# ATSAME51J18A register map
Vendor: Microchip Technology; Series: SAME51; File version: 0
CPU: CM4 r0p1, selectable endian, MPU, FPU, 3 interrupt priority bits
Registers are 32-bit, read-write, reset 0x0 unless marked. A register's access mark holds for its fields unless they carry their own. Offsets are from the block's base; [hi:lo] are bit positions; 'fields as' and 'values as' point back to an identical list.

## RAMECC
Base 0x41020000; register names take the prefix RAMECC_
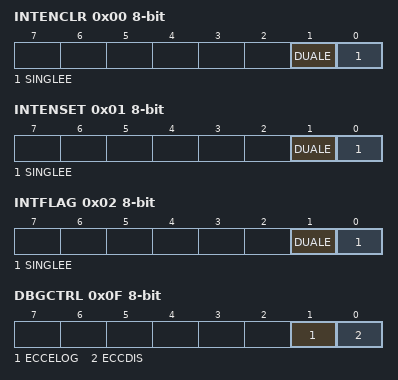
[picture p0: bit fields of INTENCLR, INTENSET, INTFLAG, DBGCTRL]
0x00 INTENCLR 8-bit — Interrupt Enable Clear
  [1] DUALE — Dual Bit ECC Error Interrupt Enable Clear
  [0] SINGLEE — Single Bit ECC Error Interrupt Enable Clear
0x01 INTENSET 8-bit — Interrupt Enable Set
  [1] DUALE — Dual Bit ECC Error Interrupt Enable Set
  [0] SINGLEE — Single Bit ECC Error Interrupt Enable Set
0x02 INTFLAG 8-bit — Interrupt Flag
  [1] DUALE — Dual Bit ECC Error Interrupt
  [0] SINGLEE — Single Bit ECC Error Interrupt
0x03 STATUS 8-bit ro
  [0] ECCDIS — ECC Disable
0x04 ERRADDR ro — Error Address
  [16:0] ERRADDR
0x0F DBGCTRL 8-bit — Debug Control
  [1] ECCELOG — ECC Error Log
  [0] ECCDIS — ECC Disable

## RSTC — Reset Controller
Base 0x40000C00; register names take the prefix RSTC_
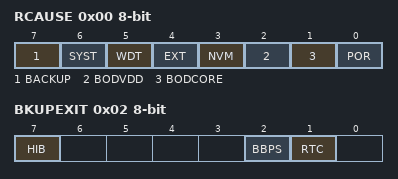
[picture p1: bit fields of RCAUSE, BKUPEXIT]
0x00 RCAUSE 8-bit ro — Reset Cause
  [7] BACKUP — Backup Reset
  [6] SYST — System Reset Request
  [5] WDT — Watchdog Reset
  [4] EXT — External Reset
  [3] NVM — NVM Reset
  [2] BODVDD — Brown Out VDD Detector Reset
  [1] BODCORE — Brown Out CORE Detector Reset
  [0] POR — Power On Reset
0x02 BKUPEXIT 8-bit ro — Backup Exit Source
  [7] HIB — Hibernate
  [2] BBPS — Battery Backup Power Switch
  [1] RTC — Real Timer Counter Interrupt

## SUPC — Supply Controller
Base 0x40001800; register names take the prefix SUPC_
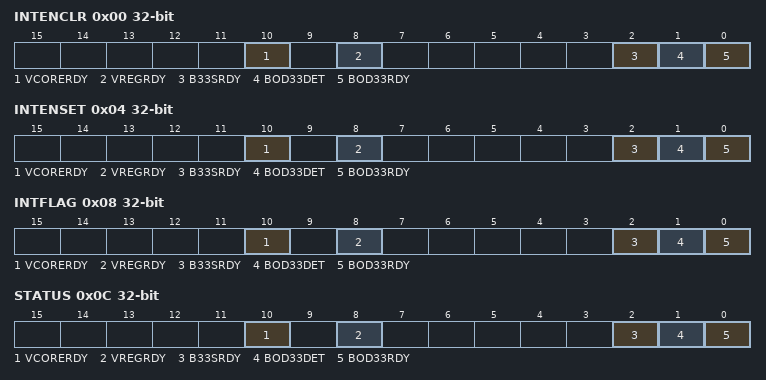
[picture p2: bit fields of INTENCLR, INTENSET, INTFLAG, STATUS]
0x00 INTENCLR — Interrupt Enable Clear
  [10] VCORERDY — VDDCORE Ready
  [8] VREGRDY — Voltage Regulator Ready
  [2] B33SRDY — BOD33 Synchronization Ready
  [1] BOD33DET — BOD33 Detection
  [0] BOD33RDY — BOD33 Ready
0x04 INTENSET — Interrupt Enable Set
  fields as INTENCLR
0x08 INTFLAG — Interrupt Flag Status and Clear
  [10] VCORERDY write-1-clears — VDDCORE Ready
  [8] VREGRDY write-1-clears — Voltage Regulator Ready
  [2] B33SRDY write-1-clears — BOD33 Synchronization Ready
  [1] BOD33DET write-1-clears — BOD33 Detection
  [0] BOD33RDY write-1-clears — BOD33 Ready
0x0C STATUS ro — Power and Clocks Status
  fields as INTENCLR
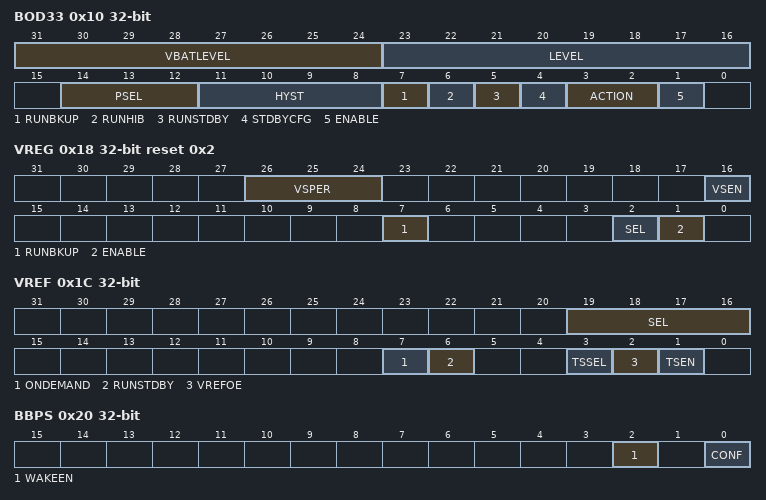
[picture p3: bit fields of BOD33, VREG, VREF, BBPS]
0x10 BOD33 — BOD33 Control
  [31:24] VBATLEVEL — Threshold Level in battery backup sleep mode for VBAT
  [23:16] LEVEL — Threshold Level for VDD
  [14:12] PSEL — Prescaler Select
    0=NODIV (Not divided); 1=DIV4 (Divide clock by 4); 2=DIV8 (Divide clock by 8); 3=DIV16 (Divide clock by 16); 4=DIV32 (Divide clock by 32); 5=DIV64 (Divide clock by 64); 6=DIV128 (Divide clock by 128); 7=DIV256 (Divide clock by 256)
  [11:8] HYST — Hysteresis value
  [7] RUNBKUP — Run in Backup mode
  [6] RUNHIB — Run in Hibernate mode
  [5] RUNSTDBY — Run in Standby mode
  [4] STDBYCFG — Configuration in Standby mode
  [3:2] ACTION — Action when Threshold Crossed
    0=NONE (No action); 1=RESET (The BOD33 generates a reset); 2=INT (The BOD33 generates an interrupt); 3=BKUP (The BOD33 puts the device in backup sleep mode)
  [1] ENABLE
0x18 VREG reset 0x2 — VREG Control
  [26:24] VSPER — Voltage Scaling Period
  [16] VSEN — Voltage Scaling Enable
  [7] RUNBKUP — Run in Backup mode
  [2] SEL — Voltage Regulator Selection
    0=LDO (LDO selection); 1=BUCK (Buck selection)
  [1] ENABLE
0x1C VREF — VREF Control
  [19:16] SEL — Voltage Reference Selection
    0=1V0 (1.0V voltage reference typical value); 1=1V1 (1.1V voltage reference typical value); 2=1V2 (1.2V voltage reference typical value); 3=1V25 (1.25V voltage reference typical value); 4=2V0 (2.0V voltage reference typical value); 5=2V2 (2.2V voltage reference typical value); 6=2V4 (2.4V voltage reference typical value); 7=2V5 (2.5V voltage reference typical value)
  [7] ONDEMAND — On Demand Contrl
  [6] RUNSTDBY — Run during Standby
  [3] TSSEL — Temperature Sensor Selection
  [2] VREFOE — Voltage Reference Output Enable
  [1] TSEN — Temperature Sensor Output Enable
0x20 BBPS — Battery Backup Power Switch
  [2] WAKEEN — Wake Enable
  [0] CONF — Battery Backup Configuration
    0=BOD33 (The power switch is handled by the BOD33); 1=FORCED (In Backup Domain, the backup domain is always supplied by battery backup power)
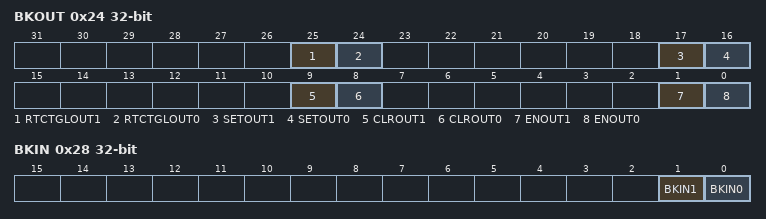
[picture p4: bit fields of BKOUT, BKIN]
0x24 BKOUT — Backup Output Control
  [25] RTCTGLOUT1 — RTC Toggle OUT1
  [24] RTCTGLOUT0 — RTC Toggle OUT0
  [17] SETOUT1
  [16] SETOUT0
  [9] CLROUT1 — Clear OUT1
  [8] CLROUT0 — Clear OUT0
  [1] ENOUT1 — Enable OUT1
  [0] ENOUT0 — Enable OUT0
0x28 BKIN ro — Backup Input Control
  [1] BKIN1 — Backup Input 1
  [0] BKIN0 — Backup Input 0

## TRNG — True Random Generator
Base 0x42002800; register names take the prefix TRNG_
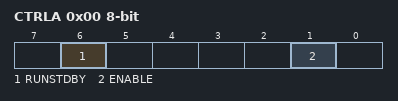
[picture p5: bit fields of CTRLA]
0x00 CTRLA 8-bit — Control A
  [6] RUNSTDBY — Run in Standby
  [1] ENABLE
0x04 EVCTRL 8-bit — Event Control
  [0] DATARDYEO — Data Ready Event Output
0x08 INTENCLR 8-bit — Interrupt Enable Clear
  [0] DATARDY — Data Ready Interrupt Enable
0x09 INTENSET 8-bit — Interrupt Enable Set
  [0] DATARDY — Data Ready Interrupt Enable
0x0A INTFLAG 8-bit — Interrupt Flag Status and Clear
  [0] DATARDY write-1-clears — Data Ready Interrupt Flag
0x20 DATA ro — Output Data

## WDT — Watchdog Timer
Base 0x40002000; register names take the prefix WDT_
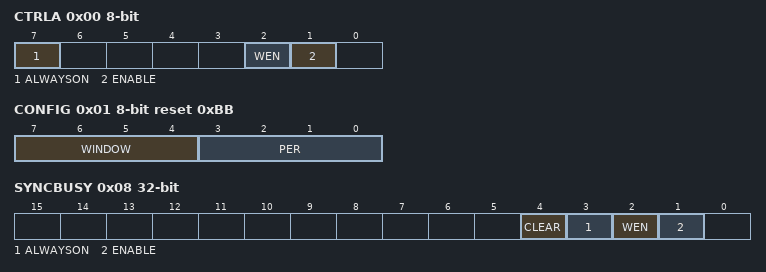
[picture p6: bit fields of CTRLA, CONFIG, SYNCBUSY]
0x00 CTRLA 8-bit — Control
  [7] ALWAYSON
  [2] WEN — Watchdog Timer Window Mode Enable
  [1] ENABLE
0x01 CONFIG 8-bit reset 0xBB — Configuration
  [7:4] WINDOW — Window Mode Time-Out Period
    0=CYC8 (8 clock cycles); 1=CYC16 (16 clock cycles); 2=CYC32 (32 clock cycles); 3=CYC64 (64 clock cycles); 4=CYC128 (128 clock cycles); 5=CYC256 (256 clock cycles); 6=CYC512 (512 clock cycles); 7=CYC1024 (1024 clock cycles); 8=CYC2048 (2048 clock cycles); 9=CYC4096 (4096 clock cycles); 10=CYC8192 (8192 clock cycles); 11=CYC16384 (16384 clock cycles)
  [3:0] PER — Time-Out Period
    values as WINDOW
0x02 EWCTRL 8-bit reset 0xB — Early Warning Interrupt Control
  [3:0] EWOFFSET — Early Warning Interrupt Time Offset
    values as CONFIG.WINDOW
0x04 INTENCLR 8-bit — Interrupt Enable Clear
  [0] EW — Early Warning Interrupt Enable
0x05 INTENSET 8-bit — Interrupt Enable Set
  [0] EW — Early Warning Interrupt Enable
0x06 INTFLAG 8-bit — Interrupt Flag Status and Clear
  [0] EW write-1-clears — Early Warning
0x08 SYNCBUSY ro — Synchronization Busy
  [4] CLEAR — Clear Synchronization Busy
  [3] ALWAYSON — Always-On Synchronization Busy
  [2] WEN — Window Enable Synchronization Busy
  [1] ENABLE — Enable Synchronization Busy
0x0C CLEAR 8-bit wo
  [7:0] CLEAR — Watchdog Clear
    165=KEY (Clear Key)
